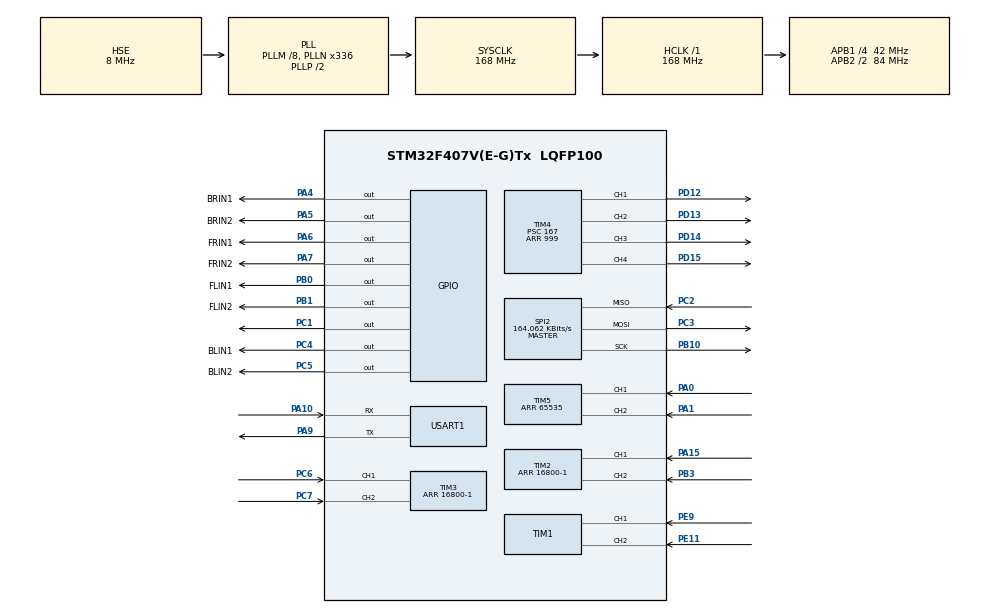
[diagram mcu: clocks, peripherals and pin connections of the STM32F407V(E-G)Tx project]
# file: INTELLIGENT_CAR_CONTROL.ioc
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Mcu.Family=STM32F4
Mcu.Name=STM32F407V(E-G)Tx
Mcu.Package=LQFP100
NVIC.PriorityGroup=NVIC_PRIORITYGROUP_4
NVIC.TIM6_DAC_IRQn=true\:0\:0\:false\:false\:true\:true\:true\:true
NVIC.USART1_IRQn=true\:0\:0\:false\:false\:true\:true\:true\:true
PA0-WKUP.Signal=S_TIM5_CH1
PA1.Signal=S_TIM5_CH2
PA10.Mode=Asynchronous
PA10.Signal=USART1_RX
PA13.Mode=Serial_Wire
PA13.Signal=SYS_JTMS-SWDIO
PA14.Mode=Serial_Wire
PA14.Signal=SYS_JTCK-SWCLK
PA15.Signal=S_TIM2_CH1_ETR
PA4.GPIO_Label=BRIN1
PA4.Signal=GPIO_Output
PA5.GPIO_Label=BRIN2
PA5.Signal=GPIO_Output
PA6.GPIO_Label=FRIN1
PA6.Signal=GPIO_Output
PA7.GPIO_Label=FRIN2
PA7.Signal=GPIO_Output
PA9.Mode=Asynchronous
PA9.Signal=USART1_TX
PB0.GPIO_Label=FLIN1
PB0.Signal=GPIO_Output
PB1.GPIO_Label=FLIN2
PB1.Signal=GPIO_Output
PB10.Mode=Full_Duplex_Master
PB10.Signal=SPI2_SCK
PB3.Signal=S_TIM2_CH2
PC1.Signal=GPIO_Output
PC2.Mode=Full_Duplex_Master
PC2.Signal=SPI2_MISO
PC3.Mode=Full_Duplex_Master
PC3.Signal=SPI2_MOSI
PC4.GPIO_Label=BLIN1
PC4.Signal=GPIO_Output
PC5.GPIO_Label=BLIN2
PC5.Signal=GPIO_Output
PC6.Signal=S_TIM3_CH1
PC7.Signal=S_TIM3_CH2
PD12.Signal=S_TIM4_CH1
PD13.Signal=S_TIM4_CH2
PD14.Signal=S_TIM4_CH3
PD15.Signal=S_TIM4_CH4
PE11.Signal=S_TIM1_CH2
PE9.Signal=S_TIM1_CH1
PH0-OSC_IN.Mode=HSE-External-Oscillator
PH0-OSC_IN.Signal=RCC_OSC_IN
PH1-OSC_OUT.Mode=HSE-External-Oscillator
PH1-OSC_OUT.Signal=RCC_OSC_OUT
ProjectManager.HeapSize=0x200
ProjectManager.StackSize=0x400
ProjectManager.TargetToolchain=STM32CubeIDE
RCC.48MHZClocksFreq_Value=84000000
RCC.AHBFreq_Value=168000000
RCC.APB1CLKDivider=RCC_HCLK_DIV4
RCC.APB1Freq_Value=42000000
RCC.APB1TimFreq_Value=84000000
RCC.APB2CLKDivider=RCC_HCLK_DIV2
RCC.APB2Freq_Value=84000000
RCC.APB2TimFreq_Value=168000000
RCC.CortexFreq_Value=168000000
RCC.HCLKFreq_Value=168000000
RCC.HSE_VALUE=8000000
RCC.HSI_VALUE=16000000
RCC.LSE_VALUE=32768
RCC.PLLM=8
RCC.PLLN=336
RCC.PLLSourceVirtual=RCC_PLLSOURCE_HSE
RCC.SYSCLKFreq_VALUE=168000000
RCC.SYSCLKSource=RCC_SYSCLKSOURCE_PLLCLK
RCC.VCOOutputFreq_Value=336000000
SH.S_TIM1_CH1.0=TIM1_CH1,Encoder_Interface
SH.S_TIM1_CH2.0=TIM1_CH2,Encoder_Interface
SH.S_TIM2_CH1_ETR.0=TIM2_CH1,Encoder_Interface
SH.S_TIM2_CH2.0=TIM2_CH2,Encoder_Interface
SH.S_TIM3_CH1.0=TIM3_CH1,Encoder_Interface
SH.S_TIM3_CH2.0=TIM3_CH2,Encoder_Interface
SH.S_TIM4_CH1.0=TIM4_CH1,PWM Generation1 CH1
SH.S_TIM4_CH2.0=TIM4_CH2,PWM Generation2 CH2
SH.S_TIM4_CH3.0=TIM4_CH3,PWM Generation3 CH3
SH.S_TIM4_CH4.0=TIM4_CH4,PWM Generation4 CH4
SH.S_TIM5_CH1.0=TIM5_CH1,Encoder_Interface
SH.S_TIM5_CH2.0=TIM5_CH2,Encoder_Interface
SPI2.BaudRatePrescaler=SPI_BAUDRATEPRESCALER_256
SPI2.CLKPolarity=SPI_POLARITY_HIGH
SPI2.CalculateBaudRate=164.062 KBits/s
SPI2.Direction=SPI_DIRECTION_2LINES
SPI2.FirstBit=SPI_FIRSTBIT_LSB
SPI2.Mode=SPI_MODE_MASTER
SPI2.VirtualType=VM_MASTER
TIM2.Period=16800-1
TIM3.Period=16800-1
TIM4.Channel-PWM\ Generation1\ CH1=TIM_CHANNEL_1
TIM4.Channel-PWM\ Generation2\ CH2=TIM_CHANNEL_2
TIM4.Channel-PWM\ Generation3\ CH3=TIM_CHANNEL_3
TIM4.Channel-PWM\ Generation4\ CH4=TIM_CHANNEL_4
TIM4.Period=999
TIM4.Prescaler=167
TIM5.EncoderMode=TIM_ENCODERMODE_TI12
TIM5.Period=65535
TIM6.Period=9999
TIM6.Prescaler=167
USART1.VirtualMode=VM_ASYNC
VP_TIM6_VS_ClockSourceINT.Mode=Enable_Timer
board=custom

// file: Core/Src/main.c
/* USER CODE BEGIN Header */
/**
  ******************************************************************************
  * @file           : main.c
  * @brief          : Main program body
  ******************************************************************************
  * @attention
  *
  * Copyright (c) 2023 STMicroelectronics.
  * All rights reserved.
  *
  * This software is licensed under terms that can be found in the LICENSE file
  * in the root directory of this software component.
  * If no LICENSE file comes with this software, it is provided AS-IS.
  *
  ******************************************************************************
  */
/* USER CODE END Header */
#include "main.h"
#include "spi.h"
#include "tim.h"
#include "usart.h"
#include "gpio.h"

/* USER CODE BEGIN Includes */
#include "motor.h"
#include "encoder.h"
#include <stdio.h>
/* USER CODE END Includes */

void SystemClock_Config(void);

/* USER CODE BEGIN 0 */
chassis_t chassis;

/* USER CODE END 0 */

int main(void) {

    /* MCU Configuration--------------------------------------------------------*/

    /* Reset of all peripherals, Initializes the Flash interface and the Systick. */
    HAL_Init();

    /* Configure the system clock */
    SystemClock_Config();

    /* Initialize all configured peripherals */
    MX_GPIO_Init();
    MX_TIM2_Init();
    MX_SPI2_Init();
    MX_USART1_UART_Init();
    MX_TIM3_Init();
    MX_TIM4_Init();
    MX_TIM5_Init();
    MX_TIM1_Init();
    MX_TIM6_Init();
    /* USER CODE BEGIN 2 */
    chassis_init();
    encoder_init();

    HAL_TIM_Base_Start_IT(&htim6);
    HAL_Delay(1000);
    /* USER CODE END 2 */

    /* Infinite loop */
    while (1) {

        /* USER CODE BEGIN 3 */
        set_chassis_direction_speed(&chassis, chassis_turn_right, 100);
        HAL_Delay(1000);

    }
    /* USER CODE END 3 */
}

void SystemClock_Config(void) {
    RCC_OscInitTypeDef RCC_OscInitStruct = {0};
    RCC_ClkInitTypeDef RCC_ClkInitStruct = {0};

    /** Configure the main internal regulator output voltage
    */
    __HAL_RCC_PWR_CLK_ENABLE();
    __HAL_PWR_VOLTAGESCALING_CONFIG(PWR_REGULATOR_VOLTAGE_SCALE1);

    /** Initializes the RCC Oscillators according to the specified parameters
    * in the RCC_OscInitTypeDef structure.
    */
    RCC_OscInitStruct.OscillatorType = RCC_OSCILLATORTYPE_HSE;
    RCC_OscInitStruct.HSEState = RCC_HSE_ON;
    RCC_OscInitStruct.PLL.PLLState = RCC_PLL_ON;
    RCC_OscInitStruct.PLL.PLLSource = RCC_PLLSOURCE_HSE;
    RCC_OscInitStruct.PLL.PLLM = 8;
    RCC_OscInitStruct.PLL.PLLN = 336;
    RCC_OscInitStruct.PLL.PLLP = RCC_PLLP_DIV2;
    RCC_OscInitStruct.PLL.PLLQ = 4;
    if (HAL_RCC_OscConfig(&RCC_OscInitStruct) != HAL_OK) {
        Error_Handler();
    }

    /** Initializes the CPU, AHB and APB buses clocks
    */
    RCC_ClkInitStruct.ClockType = RCC_CLOCKTYPE_HCLK | RCC_CLOCKTYPE_SYSCLK
                                  | RCC_CLOCKTYPE_PCLK1 | RCC_CLOCKTYPE_PCLK2;
    RCC_ClkInitStruct.SYSCLKSource = RCC_SYSCLKSOURCE_PLLCLK;
    RCC_ClkInitStruct.AHBCLKDivider = RCC_SYSCLK_DIV1;
    RCC_ClkInitStruct.APB1CLKDivider = RCC_HCLK_DIV4;
    RCC_ClkInitStruct.APB2CLKDivider = RCC_HCLK_DIV2;

    if (HAL_RCC_ClockConfig(&RCC_ClkInitStruct, FLASH_LATENCY_5) != HAL_OK) {
        Error_Handler();
    }
}

/* USER CODE BEGIN 4 */

int __io_putchar(int ch) {
    HAL_UART_Transmit(&huart1, (uint8_t *) &ch, 1, 0xffff);
    return 0;
}

/* USER CODE END 4 */

void Error_Handler(void) {
    __disable_irq();
    while (1) {
    }
}
